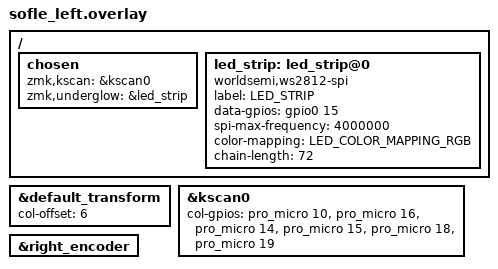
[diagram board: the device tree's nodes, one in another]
#include "sofle.dtsi"

/ {
    chosen {
        zmk,kscan = &kscan0;
        zmk,underglow = &led_strip;
    };

    led_strip: led_strip@0 {
        compatible = "worldsemi,ws2812-spi";
        label = "LED_STRIP";

        /* ⚠️ Mikoto v7.2 suele usar P0.15 o P0.06 para datos RGB */
        data-gpios = <&gpio0 15 GPIO_ACTIVE_HIGH>;

        spi-max-frequency = <4000000>;
        color-mapping = <LED_COLOR_MAPPING_RGB>;
        chain-length = <72>;
        status = "okay";
    };
};

&default_transform {
    col-offset = <6>;
};

&kscan0 {
    col-gpios =
        <&pro_micro 10 GPIO_ACTIVE_HIGH>,
        <&pro_micro 16 GPIO_ACTIVE_HIGH>,
        <&pro_micro 14 GPIO_ACTIVE_HIGH>,
        <&pro_micro 15 GPIO_ACTIVE_HIGH>,
        <&pro_micro 18 GPIO_ACTIVE_HIGH>,
        <&pro_micro 19 GPIO_ACTIVE_HIGH>;
};

&right_encoder {
    status = "okay";
};
